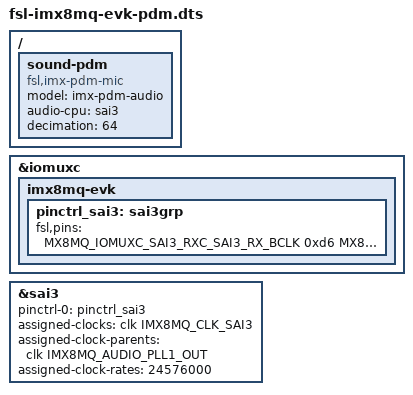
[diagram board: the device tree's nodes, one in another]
/*
 * Copyright (C) 2016 Freescale Semiconductor, Inc.
 * Copyright 2017 NXP
 *
 * This program is free software; you can redistribute it and/or
 * modify it under the terms of the GNU General Public License
 * as published by the Free Software Foundation; either version 2
 * of the License, or (at your option) any later version.
 *
 * This program is distributed in the hope that it will be useful,
 * but WITHOUT ANY WARRANTY; without even the implied warranty of
 * MERCHANTABILITY or FITNESS FOR A PARTICULAR PURPOSE.  See the
 * GNU General Public License for more details.
 */

#include "fsl-imx8mq-evk.dts"

/ {
	sound-pdm {
		compatible = "fsl,imx-pdm-mic";
		model = "imx-pdm-audio";
		audio-cpu = <&sai3>;
		decimation = <64>;
		status = "okay";
	};
};

&iomuxc {
	imx8mq-evk {
		pinctrl_sai3: sai3grp {
			fsl,pins = <
				MX8MQ_IOMUXC_SAI3_RXC_SAI3_RX_BCLK	0xd6
				MX8MQ_IOMUXC_SAI3_RXD_SAI3_RX_DATA0	0xd6
			>;
		};
	};
};

&sai3 {
	pinctrl-names = "default";
	pinctrl-0 = <&pinctrl_sai3>;
	assigned-clocks = <&clk IMX8MQ_CLK_SAI3>;
	assigned-clock-parents = <&clk IMX8MQ_AUDIO_PLL1_OUT>;
	assigned-clock-rates = <24576000>;
	status = "okay";
};
